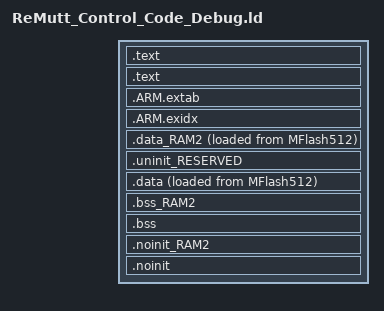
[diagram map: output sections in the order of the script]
/*
 * GENERATED FILE - DO NOT EDIT
 * (c) Code Red Technologies Ltd, 2008-2014
 * (c) NXP Semiconductors 2013-2014
 * Generated linker script file for LPC1788
 * Created from generic_c.ld (LPCXpresso v6.0 (2 [Build 151] [2013-09-18] ))
 * By LPCXpresso v6.0.2 [Build 151] [2013-09-18]  on Thu Apr 17 14:45:22 PDT 2014
 */


INCLUDE "ReMutt_Control_Code_Debug_lib.ld"
INCLUDE "ReMutt_Control_Code_Debug_mem.ld"

ENTRY(ResetISR)

SECTIONS
{

    /* MAIN TEXT SECTION */    
    .text : ALIGN(4)
    {
        FILL(0xff)
        __vectors_start__ = ABSOLUTE(.) ;
        KEEP(*(.isr_vector))
        
        /* Global Section Table */
        . = ALIGN(4) ;
        __section_table_start = .;
        __data_section_table = .;
        LONG(LOADADDR(.data));
        LONG(    ADDR(.data)) ;
        LONG(  SIZEOF(.data));
        LONG(LOADADDR(.data_RAM2));
        LONG(    ADDR(.data_RAM2)) ;
        LONG(  SIZEOF(.data_RAM2));
        __data_section_table_end = .;
        __bss_section_table = .;
        LONG(    ADDR(.bss));
        LONG(  SIZEOF(.bss));
        LONG(    ADDR(.bss_RAM2));
        LONG(  SIZEOF(.bss_RAM2));
        __bss_section_table_end = .;
        __section_table_end = . ;
        /* End of Global Section Table */
        

        *(.after_vectors*)
        
        /* Code Read Protect data */
        . = 0x000002FC ;
        PROVIDE(__CRP_WORD_START__ = .) ;
        KEEP(*(.crp))
        PROVIDE(__CRP_WORD_END__ = .) ;
        ASSERT(!(__CRP_WORD_START__ == __CRP_WORD_END__), "Linker CRP Enabled, but no CRP_WORD provided within application");
        /* End of Code Read Protect */
        
    } >MFlash512
    
    .text : ALIGN(4)    
    {
         *(.text*)
        *(.rodata .rodata.*)
        . = ALIGN(4);
        
    } > MFlash512

    /*
     * for exception handling/unwind - some Newlib functions (in common
     * with C++ and STDC++) use this. 
     */
    .ARM.extab : ALIGN(4)
    {
    	*(.ARM.extab* .gnu.linkonce.armextab.*)
    } > MFlash512
    __exidx_start = .;
    
    .ARM.exidx : ALIGN(4)
    {
    	*(.ARM.exidx* .gnu.linkonce.armexidx.*)
    } > MFlash512
    __exidx_end = .;
    
    _etext = .;
        
    
    /* DATA section for RamPeriph32 */
    .data_RAM2 : ALIGN(4)
    {
       FILL(0xff)
    	*(.data.$RAM2*)
    	*(.data.$RamPeriph32*)
       . = ALIGN(4) ;
    } > RamPeriph32 AT>MFlash512
    
    /* MAIN DATA SECTION */
    

    .uninit_RESERVED : ALIGN(4)
    {
        KEEP(*(.bss.$RESERVED*))
        . = ALIGN(4) ;
        _end_uninit_RESERVED = .;
    } > RamLoc64

	
	/* Main DATA section (RamLoc64) */
	.data : ALIGN(4)
	{
	   FILL(0xff)
	   _data = . ;
	   *(vtable)
	   *(.data*)
	   . = ALIGN(4) ;
	   _edata = . ;
	} > RamLoc64 AT>MFlash512

    /* BSS section for RamPeriph32 */
    .bss_RAM2 : ALIGN(4)
    {
    	*(.bss.$RAM2*)
    	*(.bss.$RamPeriph32*)
       . = ALIGN(4) ;
    } > RamPeriph32

    /* MAIN BSS SECTION */
    .bss : ALIGN(4)
    {
        _bss = .;
        *(.bss*)
        *(COMMON)
        . = ALIGN(4) ;
        _ebss = .;
        PROVIDE(end = .);
    } > RamLoc64
        
    /* NOINIT section for RamPeriph32 */
    .noinit_RAM2 (NOLOAD) : ALIGN(4)
    {
    	*(.noinit.$RAM2*)
    	*(.noinit.$RamPeriph32*)
       . = ALIGN(4) ;
    } > RamPeriph32 
    
    /* DEFAULT NOINIT SECTION */
    .noinit (NOLOAD): ALIGN(4)
    {
        _noinit = .;
        *(.noinit*) 
         . = ALIGN(4) ;
        _end_noinit = .;
    } > RamLoc64
    
    PROVIDE(_pvHeapStart = .);
    PROVIDE(_vStackTop = __top_RamLoc64 - 0);
}
